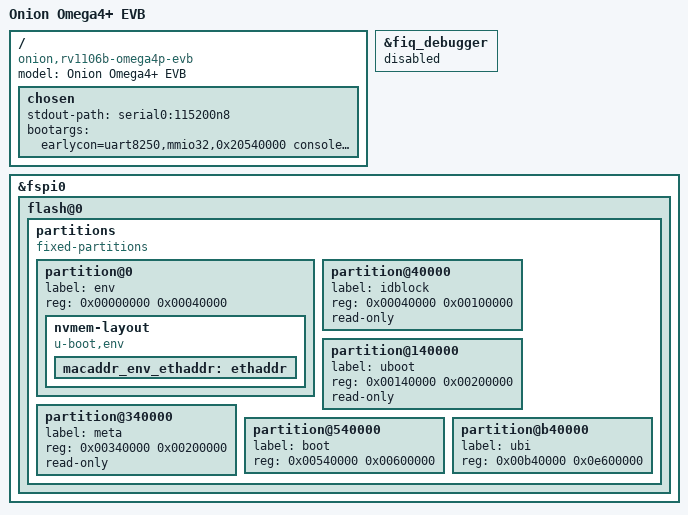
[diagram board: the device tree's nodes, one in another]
// SPDX-License-Identifier: (GPL-2.0+ OR MIT)
/* Omega4+ shares Omega4 EVB wiring, including the integrated Ethernet PHY.
 * DDR3 initialization (v1.07, 667 MHz) is performed by the vendor loader.
 * Do not include the SDK RV1106B EVB tree: it removes the Ethernet controller.
 */
#include "rv1103b-omega4-evb.dts"

/ {
	model = "Onion Omega4+ EVB";
	compatible = "onion,rv1106b-omega4p-evb", "rockchip,rv1106b";

	chosen {
		stdout-path = "serial0:115200n8";
		bootargs = "earlycon=uart8250,mmio32,0x20540000 console=ttyS0,115200n8";
	};
};

/* Use the standard UART driver and retain a single owner of UART0. */
&fiq_debugger {
	status = "disabled";
};

/* Preserve the verified SDK loader, U-Boot, meta and boot offsets. Replace
 * the SDK rootfs + userdata with UBI, retaining its end-of-flash margin.
 */
&fspi0 {
	flash@0 {
		/delete-node/ partitions;
		partitions {
			compatible = "fixed-partitions";
			#address-cells = <1>;
			#size-cells = <1>;

			partition@0 {
				label = "env";
				reg = <0x00000000 0x00040000>;
				nvmem-layout {
					compatible = "u-boot,env";
					macaddr_env_ethaddr: ethaddr {
						#nvmem-cell-cells = <1>;
					};
				};
			};
			partition@40000 {
				label = "idblock";
				reg = <0x00040000 0x00100000>;
				read-only;
			};
			partition@140000 {
				label = "uboot";
				reg = <0x00140000 0x00200000>;
				read-only;
			};
			partition@340000 {
				label = "meta";
				reg = <0x00340000 0x00200000>;
				read-only;
			};
			partition@540000 {
				label = "boot";
				reg = <0x00540000 0x00600000>;
			};
			partition@b40000 {
				label = "ubi";
				reg = <0x00b40000 0x0e600000>;
			};
		};
	};
};
